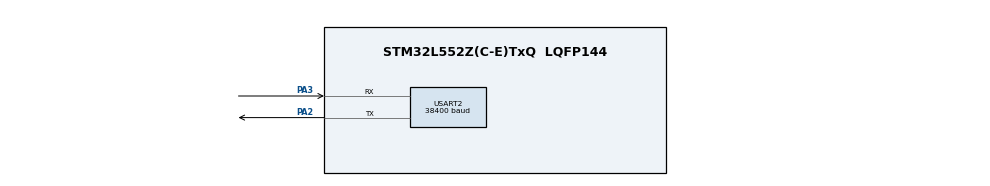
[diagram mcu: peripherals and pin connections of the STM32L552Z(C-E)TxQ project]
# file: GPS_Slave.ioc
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Mcu.Family=STM32L5
Mcu.Name=STM32L552Z(C-E)TxQ
Mcu.Package=LQFP144
NVIC.PriorityGroup=NVIC_PRIORITYGROUP_3
NVIC.USART2_IRQn=true\:0\:0\:false\:false\:true\:true\:true
PA2.Mode=Asynchronous
PA2.Signal=USART2_TX
PA3.Mode=Asynchronous
PA3.Signal=USART2_RX
ProjectManager.HeapSize=0x200
ProjectManager.StackSize=0x400
ProjectManager.TargetToolchain=STM32CubeIDE
RCC.HSE_VALUE=16000000
RCC.HSI48_VALUE=48000000
RCC.HSI_VALUE=16000000
RCC.LSE_VALUE=32768
RCC.MSI_VALUE=4000000
RCC.VCOOutputFreq_Value=32000000
USART2.BaudRate=38400
USART2.VirtualMode-Asynchronous=VM_ASYNC
VP_PWR_VS_DBSignals.Mode=DisableDeadBatterySignals
VP_PWR_VS_SECSignals.Mode=Security/Privilege
board=custom

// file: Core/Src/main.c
/* USER CODE BEGIN Header */
/**
  ******************************************************************************
  * @file           : main.c
  * @brief          : Main program body
  ******************************************************************************
  * @attention
  *
  * Copyright (c) 2022 STMicroelectronics.
  * All rights reserved.
  *
  * This software is licensed under terms that can be found in the LICENSE file
  * in the root directory of this software component.
  * If no LICENSE file comes with this software, it is provided AS-IS.
  *
  ******************************************************************************
  */
/* USER CODE END Header */
#include "main.h"

/* USER CODE BEGIN Includes */
#include "uartRingBuffer.h"
#include "NMEA.h"
#include "stdio.h"
#include "string.h"
/* USER CODE END Includes */

UART_HandleTypeDef huart2;

void SystemClock_Config(void);
static void MX_GPIO_Init(void);
static void MX_USART2_UART_Init(void);

/* USER CODE BEGIN 0 */
char GGA[100];
char RMC[100];
int VCCTimeout = 5000;

int flagGGA = 0, flagRMC = 0;
GPSSTRUCT gpsData;
/* USER CODE END 0 */

int main(void)
{

  /* MCU Configuration--------------------------------------------------------*/

  /* Reset of all peripherals, Initializes the Flash interface and the Systick. */
  HAL_Init();

  /* Configure the system clock */
  SystemClock_Config();

  /* Initialize all configured peripherals */
  MX_GPIO_Init();
  MX_USART2_UART_Init();

  /* Infinite loop */
  /* USER CODE BEGIN WHILE */
  while (1)
  {
	  if (Wait_for("GGA") == 1){

	 	  		  VCCTimeout = 5000;  // Reset the VCC Timeout indicating the GGA is being received

	 	  		  Copy_upto("*", GGA);
	 	  		  if (decodeGGA(GGA, &gpsData.ggastruct) == 0) flagGGA = 2;  // 2 indicates the data is valid
	 	  		  else flagGGA = 1;  // 1 indicates the data is invalid
	   }

	  if (Wait_for("RMC") == 1){

	 	  		  VCCTimeout = 5000;  // Reset the VCC Timeout indicating the RMC is being received

	 	  		  Copy_upto("*", RMC);
	 	  		  if (decodeRMC(RMC, &gpsData.rmcstruct) == 0) flagRMC = 2;  // 2 indicates the data is valid
	 	  		  else flagRMC = 1;  // 1 indicates the data is invalid
	   }
    /* USER CODE END WHILE */

  }
}

void SystemClock_Config(void)
{
  RCC_OscInitTypeDef RCC_OscInitStruct = {0};
  RCC_ClkInitTypeDef RCC_ClkInitStruct = {0};

  /** Configure the main internal regulator output voltage
  */
  if (HAL_PWREx_ControlVoltageScaling(PWR_REGULATOR_VOLTAGE_SCALE2) != HAL_OK)
  {
    Error_Handler();
  }
  /** Initializes the RCC Oscillators according to the specified parameters
  * in the RCC_OscInitTypeDef structure.
  */
  RCC_OscInitStruct.OscillatorType = RCC_OSCILLATORTYPE_MSI;
  RCC_OscInitStruct.MSIState = RCC_MSI_ON;
  RCC_OscInitStruct.MSICalibrationValue = RCC_MSICALIBRATION_DEFAULT;
  RCC_OscInitStruct.MSIClockRange = RCC_MSIRANGE_6;
  RCC_OscInitStruct.PLL.PLLState = RCC_PLL_NONE;
  if (HAL_RCC_OscConfig(&RCC_OscInitStruct) != HAL_OK)
  {
    Error_Handler();
  }
  /** Initializes the CPU, AHB and APB buses clocks
  */
  RCC_ClkInitStruct.ClockType = RCC_CLOCKTYPE_HCLK|RCC_CLOCKTYPE_SYSCLK
                              |RCC_CLOCKTYPE_PCLK1|RCC_CLOCKTYPE_PCLK2;
  RCC_ClkInitStruct.SYSCLKSource = RCC_SYSCLKSOURCE_MSI;
  RCC_ClkInitStruct.AHBCLKDivider = RCC_SYSCLK_DIV1;
  RCC_ClkInitStruct.APB1CLKDivider = RCC_HCLK_DIV1;
  RCC_ClkInitStruct.APB2CLKDivider = RCC_HCLK_DIV1;

  if (HAL_RCC_ClockConfig(&RCC_ClkInitStruct, FLASH_LATENCY_0) != HAL_OK)
  {
    Error_Handler();
  }
}

static void MX_USART2_UART_Init(void)
{

  huart2.Instance = USART2;
  huart2.Init.BaudRate = 38400;
  huart2.Init.WordLength = UART_WORDLENGTH_8B;
  huart2.Init.StopBits = UART_STOPBITS_1;
  huart2.Init.Parity = UART_PARITY_NONE;
  huart2.Init.Mode = UART_MODE_TX_RX;
  huart2.Init.HwFlowCtl = UART_HWCONTROL_NONE;
  huart2.Init.OverSampling = UART_OVERSAMPLING_16;
  huart2.Init.OneBitSampling = UART_ONE_BIT_SAMPLE_DISABLE;
  huart2.Init.ClockPrescaler = UART_PRESCALER_DIV1;
  huart2.AdvancedInit.AdvFeatureInit = UART_ADVFEATURE_NO_INIT;
  if (HAL_UART_Init(&huart2) != HAL_OK)
  {
    Error_Handler();
  }
  if (HAL_UARTEx_SetTxFifoThreshold(&huart2, UART_TXFIFO_THRESHOLD_1_8) != HAL_OK)
  {
    Error_Handler();
  }
  if (HAL_UARTEx_SetRxFifoThreshold(&huart2, UART_RXFIFO_THRESHOLD_1_8) != HAL_OK)
  {
    Error_Handler();
  }
  if (HAL_UARTEx_DisableFifoMode(&huart2) != HAL_OK)
  {
    Error_Handler();
  }

}

static void MX_GPIO_Init(void)
{

  /* GPIO Ports Clock Enable */
  __HAL_RCC_GPIOA_CLK_ENABLE();

}

void Error_Handler(void)
{
  __disable_irq();
  while (1)
  {
  }
}
